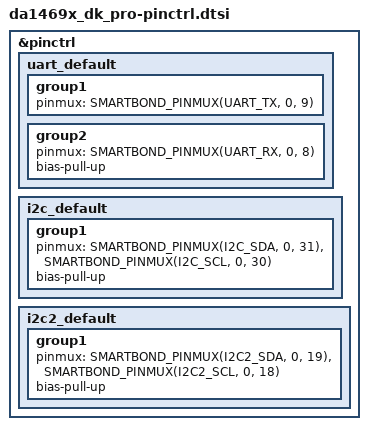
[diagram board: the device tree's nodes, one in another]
/*
 * Copyright (c) 2022 Renesas Electronics Corporation and/or its affiliates
 * SPDX-License-Identifier: Apache-2.0
 */

#include <zephyr/dt-bindings/pinctrl/smartbond-pinctrl.h>

&pinctrl {
	uart_default: uart_default {
		group1 {
			pinmux = <SMARTBOND_PINMUX(UART_TX, 0, 9)>;
		};
		group2 {
			pinmux = <SMARTBOND_PINMUX(UART_RX, 0, 8)>;
			bias-pull-up;
		};
	};

	i2c_default: i2c_default {
		group1 {
			pinmux = <SMARTBOND_PINMUX(I2C_SDA, 0, 31)>,
				<SMARTBOND_PINMUX(I2C_SCL, 0, 30)>;
			bias-pull-up;
		};
	};

	i2c2_default: i2c2_default {
		group1 {
			pinmux = <SMARTBOND_PINMUX(I2C2_SDA, 0, 19)>,
				<SMARTBOND_PINMUX(I2C2_SCL, 0, 18)>;
			bias-pull-up;
		};
	};
};
